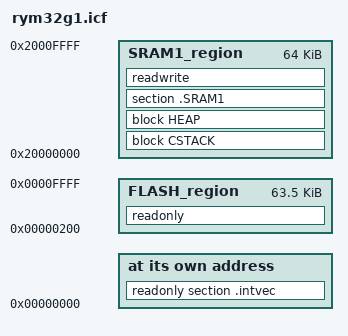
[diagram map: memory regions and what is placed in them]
define symbol    __ICFEDIT_intvec_start__          = 0x00000000;
define symbol    __ICFEDIT_region_FLASH_start__    = 0x00000200;
define symbol    __ICFEDIT_region_FLASH_end__      = 0x0000FFFF;
define symbol    __ICFEDIT_region_SRAM1_start__    = 0x20000000;
define symbol    __ICFEDIT_region_SRAM1_end__      = 0x2000FFFF;

define symbol    __ICFEDIT_size_cstack__           = 0x0800;
define symbol    __ICFEDIT_size_heap__             = 0x0200;

define memory    mem with size                     = 4G;

define region    FLASH_region                      = mem:[ from __ICFEDIT_region_FLASH_start__ to __ICFEDIT_region_FLASH_end__ ];
define region    SRAM1_region                      = mem:[ from __ICFEDIT_region_SRAM1_start__ to __ICFEDIT_region_SRAM1_end__ ];

define block     CSTACK                            with alignment = 8, size = __ICFEDIT_size_cstack__ { section CSTACK };
define block     HEAP                              with alignment = 8, size = __ICFEDIT_size_heap__   { section HEAP   };

initialize by copy { readwrite };
do not initialize  { section .noinit };

place at address mem:__ICFEDIT_intvec_start__ { readonly section .intvec };
place in FLASH_region                         { readonly };
place in SRAM1_region                         { block CSTACK, block HEAP, section .SRAM1, readwrite };
